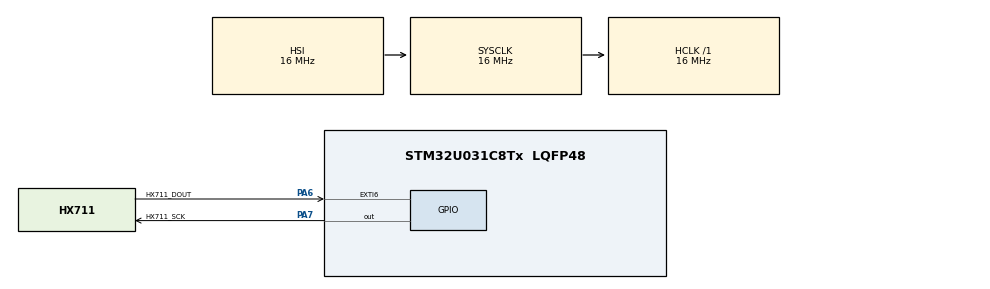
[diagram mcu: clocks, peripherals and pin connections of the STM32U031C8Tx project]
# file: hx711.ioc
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Mcu.Family=STM32U0
Mcu.Name=STM32U031C8Tx
Mcu.Package=LQFP48
NVIC.EXTI4_15_IRQn=true\:2\:0\:true\:false\:true\:true\:true\:true
NVIC.PriorityGroup=NVIC_PRIORITYGROUP_2
PA6.GPIO_Label=HX711_DOUT
PA6.Signal=GPXTI6
PA7.GPIO_Label=HX711_SCK
PA7.Signal=GPIO_Output
ProjectManager.HeapSize=0x200
ProjectManager.StackSize=0x400
ProjectManager.TargetToolchain=CMake
RCC.AHBFreq_Value=16000000
RCC.CortexFreq_Value=16000000
RCC.HCLKFreq_Value=16000000
RCC.HSE_VALUE=4000000
RCC.HSI48_VALUE=48000000
RCC.HSI_VALUE=16000000
RCC.LSE_VALUE=32768
RCC.MSI_VALUE=4000000
RCC.SYSCLKFreq_VALUE=16000000
RCC.VCOOutputFreq_Value=64000000
VP_PWR_VS_SECSignals.Mode=Security/Privilege
board=custom

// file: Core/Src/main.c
/* USER CODE BEGIN Header */
/**
  ******************************************************************************
  * @file           : main.c
  * @brief          : Main program body
  ******************************************************************************
  * @attention
  *
  * Copyright (c) 2026 STMicroelectronics.
  * All rights reserved.
  *
  * This software is licensed under terms that can be found in the LICENSE file
  * in the root directory of this software component.
  * If no LICENSE file comes with this software, it is provided AS-IS.
  *
  ******************************************************************************
  */
/* USER CODE END Header */
#include "main.h"

/* USER CODE BEGIN Includes */

#include "HX711.h"
#include "hal_weight.h"

/* USER CODE END Includes */

/* USER CODE BEGIN PV */

static HX711_HandleTypeDef g_hx711 = {0};

/* USER CODE END PV */

void SystemClock_Config(void);
static void MX_GPIO_Init(void);

int main(void)
{

  /* MCU Configuration--------------------------------------------------------*/

  /* Reset of all peripherals, Initializes the Flash interface and the Systick. */
  HAL_Init();

  /* Configure the system clock */
  SystemClock_Config();

  /* Initialize all configured peripherals */
  MX_GPIO_Init();
  /* USER CODE BEGIN 2 */

  /**
    * @brief  Initialize the HX711 stack and perform the startup tare.
    * @details The HX711 driver is bound to the GPIO pins configured by
    *          CubeMX, the weight layer is attached, and a blocking tare is
    *          executed before the main loop begins.
    */
  HX711_Init(&g_hx711,
             HX711_SCK_GPIO_Port, HX711_SCK_Pin,
             HX711_DOUT_GPIO_Port, HX711_DOUT_Pin);
  HAL_Weight_Init(&g_hx711);
  HAL_Weight_Tare();

  /* USER CODE END 2 */

  /* Infinite loop */
  while (1)
  {

    /* USER CODE BEGIN 3 */

    __WFI();

  }
  /* USER CODE END 3 */
}

void SystemClock_Config(void)
{
  RCC_OscInitTypeDef RCC_OscInitStruct = {0};
  RCC_ClkInitTypeDef RCC_ClkInitStruct = {0};

  /** Configure the main internal regulator output voltage
  */
  HAL_PWREx_ControlVoltageScaling(PWR_REGULATOR_VOLTAGE_SCALE2);

  /** Initializes the RCC Oscillators according to the specified parameters
  * in the RCC_OscInitTypeDef structure.
  */
  RCC_OscInitStruct.OscillatorType = RCC_OSCILLATORTYPE_HSI;
  RCC_OscInitStruct.HSIState = RCC_HSI_ON;
  RCC_OscInitStruct.HSICalibrationValue = RCC_HSICALIBRATION_DEFAULT;
  RCC_OscInitStruct.PLL.PLLState = RCC_PLL_NONE;
  if (HAL_RCC_OscConfig(&RCC_OscInitStruct) != HAL_OK)
  {
    Error_Handler();
  }

  /** Initializes the CPU, AHB and APB buses clocks
  */
  RCC_ClkInitStruct.ClockType = RCC_CLOCKTYPE_HCLK|RCC_CLOCKTYPE_SYSCLK
                              |RCC_CLOCKTYPE_PCLK1;
  RCC_ClkInitStruct.SYSCLKSource = RCC_SYSCLKSOURCE_HSI;
  RCC_ClkInitStruct.AHBCLKDivider = RCC_SYSCLK_DIV1;
  RCC_ClkInitStruct.APB1CLKDivider = RCC_HCLK_DIV1;

  if (HAL_RCC_ClockConfig(&RCC_ClkInitStruct, FLASH_LATENCY_1) != HAL_OK)
  {
    Error_Handler();
  }
}

static void MX_GPIO_Init(void)
{
  GPIO_InitTypeDef GPIO_InitStruct = {0};

  /* GPIO Ports Clock Enable */
  __HAL_RCC_GPIOA_CLK_ENABLE();

  /*Configure GPIO pin Output Level */
  HAL_GPIO_WritePin(HX711_SCK_GPIO_Port, HX711_SCK_Pin, GPIO_PIN_RESET);

  /*Configure GPIO pin : HX711_DOUT_Pin */
  GPIO_InitStruct.Pin = HX711_DOUT_Pin;
  GPIO_InitStruct.Mode = GPIO_MODE_IT_FALLING;
  GPIO_InitStruct.Pull = GPIO_NOPULL;
  HAL_GPIO_Init(HX711_DOUT_GPIO_Port, &GPIO_InitStruct);

  /*Configure GPIO pin : HX711_SCK_Pin */
  GPIO_InitStruct.Pin = HX711_SCK_Pin;
  GPIO_InitStruct.Mode = GPIO_MODE_OUTPUT_PP;
  GPIO_InitStruct.Pull = GPIO_NOPULL;
  GPIO_InitStruct.Speed = GPIO_SPEED_FREQ_LOW;
  HAL_GPIO_Init(HX711_SCK_GPIO_Port, &GPIO_InitStruct);

  /* EXTI interrupt init*/
  HAL_NVIC_SetPriority(EXTI4_15_IRQn, 2, 0);
  HAL_NVIC_EnableIRQ(EXTI4_15_IRQn);

}

/* USER CODE BEGIN 4 */

/**
  * @brief  Route the HX711 data-ready EXTI event into the driver.
  * @param  GPIO_Pin  EXTI source pin number.
  * @retval None
  */
void HAL_GPIO_EXTI_Callback(uint16_t GPIO_Pin)
{
  if (GPIO_Pin == HX711_DOUT_Pin)
  {
    HX711_OnDoutLowIsr(&g_hx711);
  }
}

/* USER CODE END 4 */

void Error_Handler(void)
{
  __disable_irq();
  while (1)
  {
  }
}
